# STM32F107xx register map
File version: 1.2
CPU: 
Registers are 32-bit, read-write, reset 0x0 unless marked. A register's access mark holds for its fields unless they carry their own. Offsets are from the block's base; [hi:lo] are bit positions; {n}, {i} and the like mark numbered series.

## DBG — Debug support
Base 0xE0042000
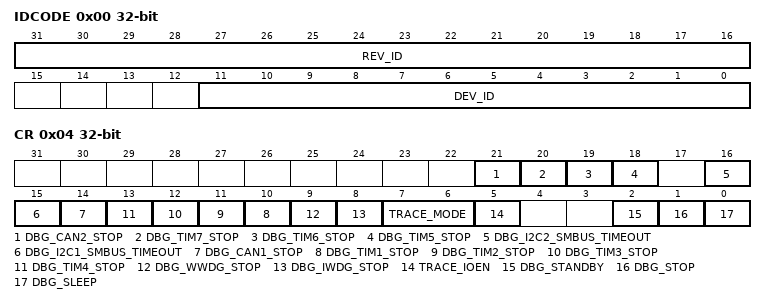
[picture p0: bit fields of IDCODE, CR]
0x00 IDCODE ro — DBGMCU_IDCODE
  [31:16] REV_ID, [11:0] DEV_ID
0x04 CR — DBGMCU_CR
  [21] DBG_CAN2_STOP, [20] DBG_TIM7_STOP, [19] DBG_TIM6_STOP, [18] DBG_TIM5_STOP, [16] DBG_I2C2_SMBUS_TIMEOUT, [15] DBG_I2C1_SMBUS_TIMEOUT, [14] DBG_CAN1_STOP, [n+9] DBG_TIM{n}_STOP (n=1..4), [9] DBG_WWDG_STOP, [8] DBG_IWDG_STOP, [7:6] TRACE_MODE, [5] TRACE_IOEN, [2] DBG_STANDBY, [1] DBG_STOP, [0] DBG_SLEEP

## UART4 — Universal asynchronous receiver transmitter
Base 0x40004C00
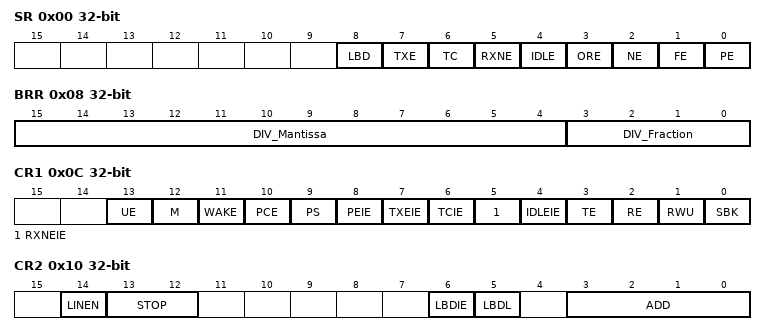
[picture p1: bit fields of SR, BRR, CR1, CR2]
0x00 SR access per field — UART4 SR
  [8] LBD rw — LIN break detection flag
  [7] TXE ro — Transmit data register empty
  [6] TC rw — Transmission complete
  [5] RXNE rw — Read data register not empty
  [4] IDLE ro — IDLE line detected
  [3] ORE ro — Overrun error
  [2] NE ro — Noise error flag
  [1] FE ro — Framing error
  [0] PE ro — Parity error
0x04 DR — UART4 DR
  [8:0] DR
0x08 BRR — UART4 BRR
  [15:4] DIV_Mantissa, [3:0] DIV_Fraction
0x0C CR1 — UART4 CR1
  [13] UE — USART enable
  [12] M — Word length
  [11] WAKE — Wakeup method
  [10] PCE — Parity control enable
  [9] PS — Parity selection
  [8] PEIE — PE interrupt enable
  [7] TXEIE — TXE interrupt enable
  [6] TCIE — Transmission complete interrupt enable
  [5] RXNEIE — RXNE interrupt enable
  [4] IDLEIE — IDLE interrupt enable
  [3] TE — Transmitter enable
  [2] RE — Receiver enable
  [1] RWU — Receiver wakeup
  [0] SBK — Send break
0x10 CR2 — UART4 CR2
  [14] LINEN — LIN mode enable
  [13:12] STOP — STOP bits
  [6] LBDIE — LIN break detection interrupt enable
  [5] LBDL — lin break detection length
  [3:0] ADD — Address of the USART node
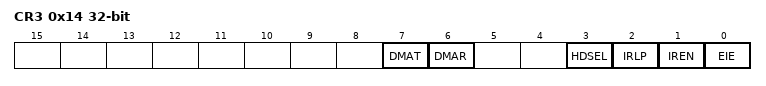
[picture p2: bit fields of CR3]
0x14 CR3 — UART4 CR3
  [7] DMAT — DMA enable transmitter
  [6] DMAR — DMA enable receiver
  [3] HDSEL — Half-duplex selection
  [2] IRLP — IrDA low-power
  [1] IREN — IrDA mode enable
  [0] EIE — Error interrupt enable

## UART5 — Universal asynchronous receiver transmitter
Base 0x40005000
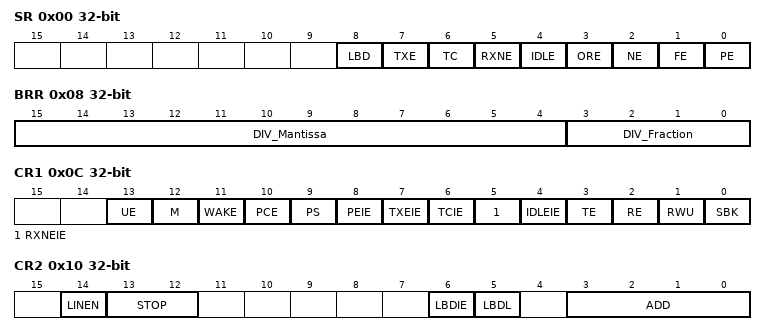
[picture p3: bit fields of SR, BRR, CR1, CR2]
0x00 SR access per field — UART5 SR
  [8] LBD rw, [7] TXE ro, [6] TC rw, [5] RXNE rw, [4] IDLE ro, [3] ORE ro, [2] NE ro, [1] FE ro, [0] PE ro
0x04 DR — UART5 DR
  [8:0] DR
0x08 BRR — UART5 BRR
  [15:4] DIV_Mantissa, [3:0] DIV_Fraction
0x0C CR1 — UART5 CR1
  [13] UE, [12] M, [11] WAKE, [10] PCE, [9] PS, [8] PEIE, [7] TXEIE, [6] TCIE, [5] RXNEIE, [4] IDLEIE, [3] TE, [2] RE, [1] RWU, [0] SBK
0x10 CR2 — UART5 CR2
  [14] LINEN, [13:12] STOP, [6] LBDIE, [5] LBDL, [3:0] ADD
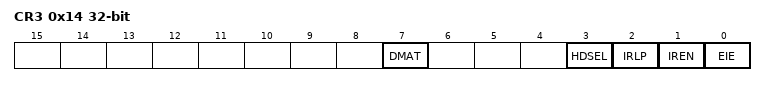
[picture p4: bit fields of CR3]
0x14 CR3 — UART5 CR3
  [7] DMAT — DMA enable transmitter
  [3] HDSEL — Half-duplex selection
  [2] IRLP — IrDA low-power
  [1] IREN — IrDA mode enable
  [0] EIE — Error interrupt enable

## CRC — CRC calculation unit
Base 0x40023000
0x00 DR reset 0xFFFFFFFF — Data register
  [31:0] DR — Data Register
0x04 IDR — Independent Data register
  [7:0] IDR
0x08 CR wo — Control register
  [0] RESET — Reset bit

## FLASH
Base 0x40022000
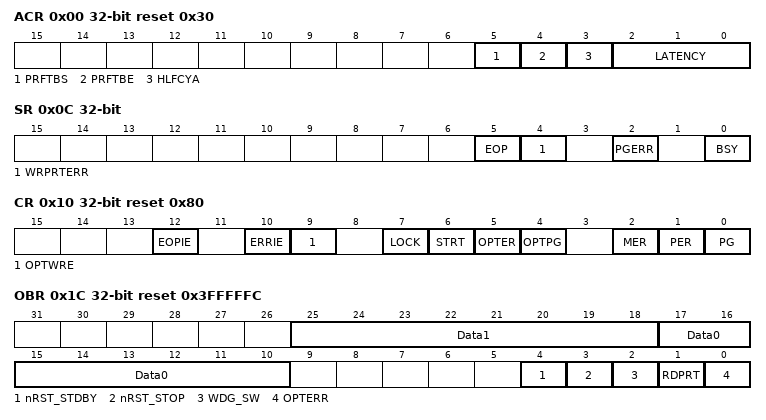
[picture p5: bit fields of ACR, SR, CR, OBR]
0x00 ACR access per field reset 0x30 — Flash access control register
  [5] PRFTBS ro — Prefetch buffer status
  [4] PRFTBE rw — Prefetch buffer enable
  [3] HLFCYA rw — Flash half cycle access enable
  [2:0] LATENCY rw
0x04 KEYR wo — Flash key register
  [31:0] KEY — FPEC key
0x08 OPTKEYR wo — Flash option key register
  [31:0] OPTKEY — Option byte key
0x0C SR access per field — Status register
  [5] EOP rw — End of operation
  [4] WRPRTERR rw — Write protection error
  [2] PGERR rw — Programming error
  [0] BSY ro — Busy
0x10 CR reset 0x80 — Control register
  [12] EOPIE — End of operation interrupt enable
  [10] ERRIE — Error interrupt enable
  [9] OPTWRE — Option bytes write enable
  [7] LOCK
  [6] STRT — Start
  [5] OPTER — Option byte erase
  [4] OPTPG — Option byte programming
  [2] MER — Mass Erase
  [1] PER — Page Erase
  [0] PG — Programming
0x14 AR wo — Flash address register
  [31:0] FAR — Flash Address
0x1C OBR ro reset 0x3FFFFFC — Option byte register
  [25:18] Data1
  [17:10] Data0
  [4] nRST_STDBY
  [3] nRST_STOP
  [2] WDG_SW
  [1] RDPRT — Read protection
  [0] OPTERR — Option byte error
0x20 WRPR ro reset 0xFFFFFFFF — Write protection register
  [31:0] WRP — Write protect

## NVIC — Nested Vectored Interrupt Controller
Base 0xE000E000
0x04 ICTR ro — Interrupt Controller Type Register
  [3:0] INTLINESNUM — Total number of interrupt lines in groups
{0x100+4i} ISER{i} (i=0..2) — Interrupt Set-Enable Register
  [31:0] SETENA
{0x180+4i} ICER{i} (i=0..2) — Interrupt Clear-Enable Register
  [31:0] CLRENA
{0x200+4i} ISPR{i} (i=0..2) — Interrupt Set-Pending Register
  [31:0] SETPEND
{0x280+4i} ICPR{i} (i=0..2) — Interrupt Clear-Pending Register
  [31:0] CLRPEND
{0x300+4i} IABR{i} ro (i=0..2) — Interrupt Active Bit Register
  [31:0] ACTIVE
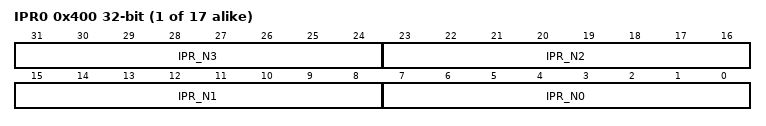
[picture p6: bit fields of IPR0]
{0x400+4i} IPR{i} (i=0..16) — Interrupt Priority Register
  [8n+7:8n] IPR_N{n} (n=0..3)
0xF00 STIR wo — Software Triggered Interrupt Register
  [8:0] INTID — interrupt to be triggered
